AUTOSAR XML (schema 4-0-3)
package /ComponentTypes
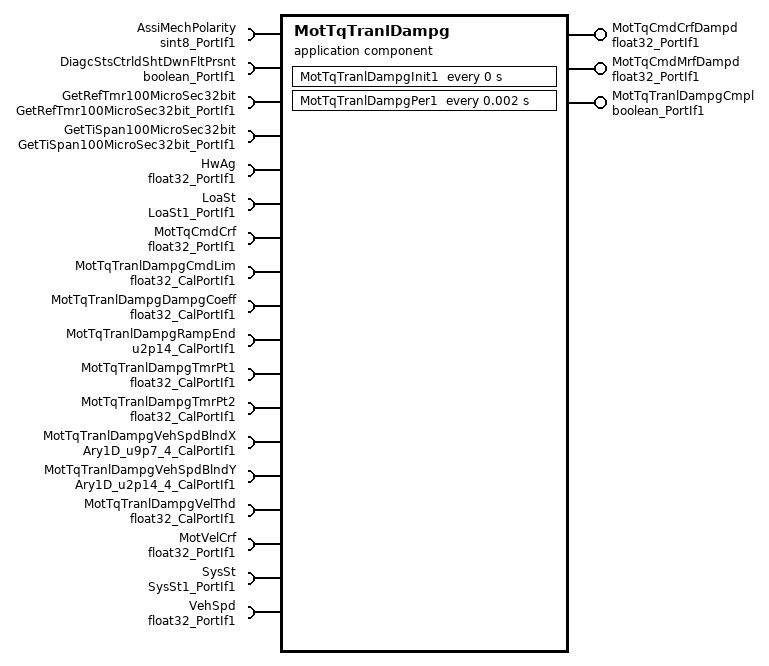
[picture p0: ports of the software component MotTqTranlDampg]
  application sw component type MotTqTranlDampg
    provide port MotTqCmdCrfDampd: nonqueued-sender-com-spec{data-element=Val, init-value=0}, provided-interface=float32_PortIf1
    provide port MotTqCmdMrfDampd: nonqueued-sender-com-spec{data-element=Val, init-value=0}, provided-interface=float32_PortIf1
    provide port MotTqTranlDampgCmpl: nonqueued-sender-com-spec{data-element=Logl, init-value=0}, provided-interface=boolean_PortIf1
    18 x require port:
      AssiMechPolarity: nonqueued-receiver-com-spec{data-element=Val, filter=data-filter-type=ALWAYS, init-value=1}, required-interface=sint8_PortIf1
      DiagcStsCtrldShtDwnFltPrsnt: nonqueued-receiver-com-spec{data-element=Logl, filter=data-filter-type=ALWAYS, init-value=0}, required-interface=boolean_PortIf1
      GetRefTmr100MicroSec32bit: client-com-spec=Oper, required-interface=GetRefTmr100MicroSec32bit_PortIf1
      GetTiSpan100MicroSec32bit: client-com-spec=Oper, required-interface=GetTiSpan100MicroSec32bit_PortIf1
      HwAg: nonqueued-receiver-com-spec{data-element=Val, filter=data-filter-type=ALWAYS, init-value=0}, required-interface=float32_PortIf1
      LoaSt: nonqueued-receiver-com-spec{data-element=Val, filter=data-filter-type=ALWAYS, init-value=0}, required-interface=LoaSt1_PortIf1
      MotTqCmdCrf: nonqueued-receiver-com-spec{data-element=Val, filter=data-filter-type=ALWAYS, init-value=0}, required-interface=float32_PortIf1
      MotTqTranlDampgCmdLim: parameter-require-com-spec{init-value=3, parameter=Val}, required-interface=float32_CalPortIf1
      MotTqTranlDampgDampgCoeff: parameter-require-com-spec{init-value=0.036, parameter=Val}, required-interface=float32_CalPortIf1
      MotTqTranlDampgRampEnd: parameter-require-com-spec{init-value=0, parameter=Val}, required-interface=u2p14_CalPortIf1
      MotTqTranlDampgTmrPt1: parameter-require-com-spec{init-value=100, parameter=Val}, required-interface=float32_CalPortIf1
      MotTqTranlDampgTmrPt2: parameter-require-com-spec{init-value=1000, parameter=Val}, required-interface=float32_CalPortIf1
      MotTqTranlDampgVehSpdBlndX: parameter-require-com-spec{init-value=[0, 1280, 2560, 12800], parameter=Ary1D}, required-interface=Ary1D_u9p7_4_CalPortIf1
      MotTqTranlDampgVehSpdBlndY: parameter-require-com-spec{init-value=[16384, 16384, 0, 0], parameter=Ary1D}, required-interface=Ary1D_u2p14_4_CalPortIf1
      MotTqTranlDampgVelThd: parameter-require-com-spec{init-value=2.3, parameter=Val}, required-interface=float32_CalPortIf1
      MotVelCrf: nonqueued-receiver-com-spec{data-element=Val, filter=data-filter-type=ALWAYS, init-value=0}, required-interface=float32_PortIf1
      SysSt: nonqueued-receiver-com-spec{data-element=Val, filter=data-filter-type=ALWAYS, init-value=3}, required-interface=SysSt1_PortIf1
      VehSpd: nonqueued-receiver-com-spec{data-element=Val, filter=data-filter-type=ALWAYS, init-value=0}, required-interface=float32_PortIf1
    behavior MotTqTranlDampg_InternalBehavior
      ar-typed-per-instance-memorys:
        9 x data, all with sw-calibration-access=READ-ONLY:
          DiagStsPrev: type=boolean
          dMotTqTranlDampgCmdCtrld: type=float32
          dMotTqTranlDampgSignPhaSca: type=float32
          dMotTqTranlDampgTiElpd: type=float32
          dMotTqTranlDampgTmrEna: type=boolean
          dMotTqTranlDampgVelDampgCmd: type=float32
          LoaStPrev: type=LoaSt1
          StLtchPrev: type=boolean
          TmrRefTi: type=uint32
      timing event MotTqTranlDampg_InitEvent: start-on-event=MotTqTranlDampgInit1, period=0
      timing event TMT_MotTqTranlDampgPer1: start-on-event=MotTqTranlDampgPer1, period=0.002
      explicit-inter-runnable-variables:
        data CtrldDampgScaX: type=Ary1D_u16p0_2, init-value=[0, 100]
        data CtrldDampgScaY: type=Ary1D_u2p14_2, init-value=[16384, 0]
      runnable MotTqTranlDampgInit1
        written-local-variables:
          access WRITE_CtrldDampgScaX: accessed-variable=CtrldDampgScaX
          access WRITE_CtrldDampgScaY: accessed-variable=CtrldDampgScaY
      runnable MotTqTranlDampgPer1
        data-receive-point-by-arguments:
          8 x access:
            REC_AssiMechPolarity_Val: accessed-variable=AssiMechPolarity.Val
            REC_DiagcStsCtrldShtDwnFltPrsnt_Logl: accessed-variable=DiagcStsCtrldShtDwnFltPrsnt.Logl
            REC_HwAg_Val: accessed-variable=HwAg.Val
            REC_LoaSt_Val: accessed-variable=LoaSt.Val
            REC_MotTqCmdCrf_Val: accessed-variable=MotTqCmdCrf.Val
            REC_MotVelCrf_Val: accessed-variable=MotVelCrf.Val
            REC_SysSt_Val: accessed-variable=SysSt.Val
            REC_VehSpd_Val: accessed-variable=VehSpd.Val
        data-send-points:
          access SEND_MotTqCmdCrfDampd_Val: accessed-variable=MotTqCmdCrfDampd.Val
          access SEND_MotTqCmdMrfDampd_Val: accessed-variable=MotTqCmdMrfDampd.Val
          access SEND_MotTqTranlDampgCmpl_Logl: accessed-variable=MotTqTranlDampgCmpl.Logl
        read-local-variables:
          access READ_CtrldDampgScaX: accessed-variable=CtrldDampgScaX
          access READ_CtrldDampgScaY: accessed-variable=CtrldDampgScaY
        sync call SC_GetRefTmr100MicroSec32bit_Oper: operation=GetRefTmr100MicroSec32bit.Oper, timeout=0
        sync call SC_GetTiSpan100MicroSec32bit_Oper: operation=GetTiSpan100MicroSec32bit.Oper, timeout=0
  swc implementation MotTqTranlDampg_Implementation: behavior=MotTqTranlDampg_InternalBehavior
    code-descriptors:
      code Default: artifact-descriptors=autosar-engineering-object={short-label=Default, category=SWSRC}
